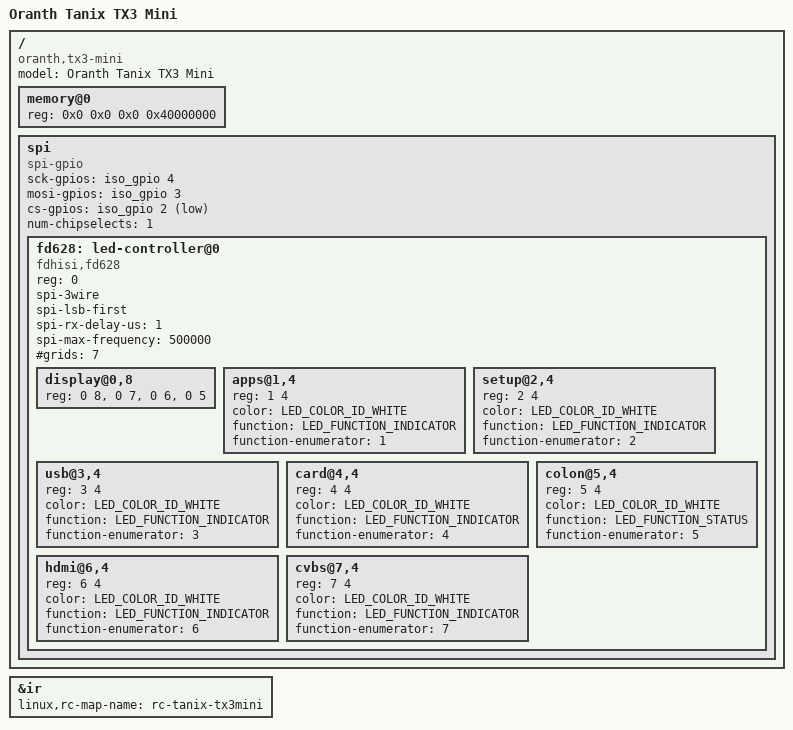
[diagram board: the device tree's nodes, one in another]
// SPDX-License-Identifier: (GPL-2.0+ OR MIT)
/*
 * Copyright (c) 2018 Martin Blumenstingl <martin.blumenstingl@googlemail.com>.
 * Based on meson-gxl-s905d-p231.dts:
 * - Copyright (c) 2016 Endless Computers, Inc.
 *   Author: Carlo Caione <carlo@endlessm.com>
 */

/dts-v1/;

#include "meson-gxl-s905x.dtsi"
#include "meson-gx-p23x-q20x.dtsi"
#include <dt-bindings/gpio/gpio.h>
#include <dt-bindings/leds/common.h>

/ {
	compatible = "oranth,tx3-mini", "amlogic,s905w", "amlogic,meson-gxl";
	model = "Oranth Tanix TX3 Mini";

	memory@0 {
		device_type = "memory";
		reg = <0x0 0x0 0x0 0x40000000>; /* 1 GiB or 2 GiB */
	};

	spi {
		compatible = "spi-gpio";
		sck-gpios = <&iso_gpio 4 GPIO_ACTIVE_HIGH>;
		mosi-gpios = <&iso_gpio 3 GPIO_ACTIVE_HIGH>;
		cs-gpios = <&iso_gpio 2 GPIO_ACTIVE_LOW>;
		num-chipselects = <1>;
		#address-cells = <1>;
		#size-cells = <0>;

		fd628: led-controller@0 {
			compatible = "fdhisi,fd628";
			reg = <0>;
			spi-3wire;
			spi-lsb-first;
			spi-rx-delay-us = <1>;
			spi-max-frequency = <500000>;
			#grids = <7>;
			#address-cells = <2>;
			#size-cells = <0>;

			display@0,8 {
				reg = <0 8>, <0 7>, <0 6>, <0 5>;
			};

			apps@1,4 {
				reg = <1 4>;
				color = <LED_COLOR_ID_WHITE>;
				function = LED_FUNCTION_INDICATOR;
				function-enumerator = <1>;
			};

			setup@2,4 {
				reg = <2 4>;
				color = <LED_COLOR_ID_WHITE>;
				function = LED_FUNCTION_INDICATOR;
				function-enumerator = <2>;
			};

			usb@3,4 {
				reg = <3 4>;
				color = <LED_COLOR_ID_WHITE>;
				function = LED_FUNCTION_INDICATOR;
				function-enumerator = <3>;
			};

			card@4,4 {
				reg = <4 4>;
				color = <LED_COLOR_ID_WHITE>;
				function = LED_FUNCTION_INDICATOR;
				function-enumerator = <4>;
			};

			colon@5,4 {
				reg = <5 4>;
				color = <LED_COLOR_ID_WHITE>;
				function = LED_FUNCTION_STATUS;
				function-enumerator = <5>;
			};

			hdmi@6,4 {
				reg = <6 4>;
				color = <LED_COLOR_ID_WHITE>;
				function = LED_FUNCTION_INDICATOR;
				function-enumerator = <6>;
			};

			cvbs@7,4 {
				reg = <7 4>;
				color = <LED_COLOR_ID_WHITE>;
				function = LED_FUNCTION_INDICATOR;
				function-enumerator = <7>;
			};
		};
	};
};

&ir {
	linux,rc-map-name = "rc-tanix-tx3mini";
};
